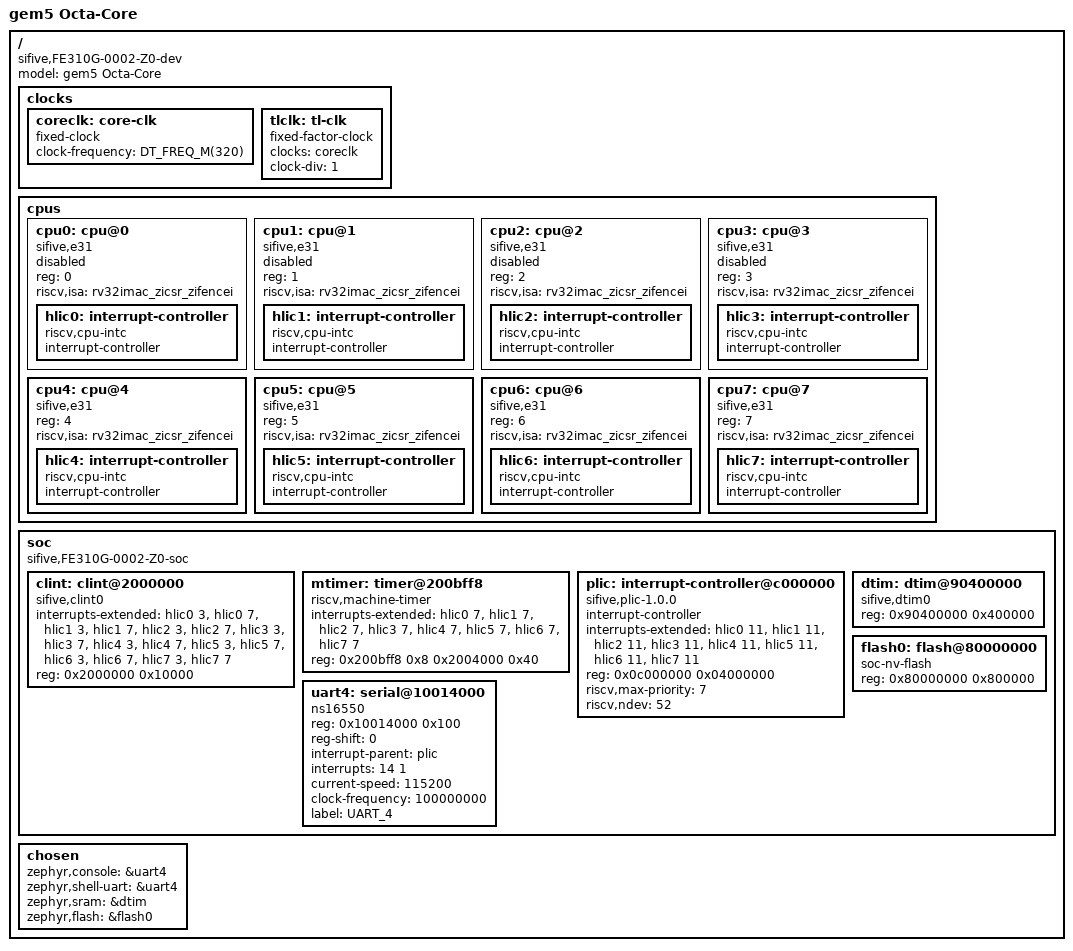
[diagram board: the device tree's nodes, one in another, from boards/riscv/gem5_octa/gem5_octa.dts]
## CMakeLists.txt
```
cmake_minimum_required(VERSION 3.20.0)
find_package(Zephyr REQUIRED HINTS $ENV{ZEPHYR_BASE})
project(smp_hello)

target_sources(app PRIVATE src/main.c)
```

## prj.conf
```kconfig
CONFIG_SMP=y
CONFIG_MP_MAX_NUM_CPUS=4
CONFIG_RV_BOOT_HART=4
CONFIG_RISCV_MACHINE_TIMER=y
CONFIG_SYS_CLOCK_TICKS_PER_SEC=100
CONFIG_XIP=n
```

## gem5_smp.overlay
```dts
/ {
	chosen {
		zephyr,console = &uart0;
		zephyr,shell-uart = &uart0;
		zephyr,sram = &dtim;
		zephyr,flash = &dtim;
	};
};

&uart0 {
    reg = <0x10014000 0x100>;
    interrupts = <14 1>;
    current-speed = <115200>;
    clock-frequency = <100000000>;
};

&dtim {
    reg = <0x90400000 0x400000>; /* 4MB Shared SRAM (Data) */
};

/delete-node/ &spi0;

/ {
    soc {
        flash0: memory@80000000 {
            compatible = "mmio-sram";
            reg = <0x80000000 0x800000>; /* 8MB Shared MRAM (Code) */
        };
    };
};
```

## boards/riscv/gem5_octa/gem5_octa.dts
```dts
/* SPDX-License-Identifier: Apache-2.0 */

/dts-v1/;

#include <zephyr/dt-bindings/gpio/gpio.h>
#include <zephyr/dt-bindings/pwm/pwm.h>
#include <freq.h>

/ {
	#address-cells = <1>;
	#size-cells = <1>;
	compatible = "sifive,FE310G-0002-Z0-dev", "fe310-dev", "sifive-dev";
	model = "gem5 Octa-Core";

	clocks {
		coreclk: core-clk {
			#clock-cells = <0>;
			compatible = "fixed-clock";
			clock-frequency = <DT_FREQ_M(320)>;
		};

		tlclk: tl-clk {
			#clock-cells = <0>;
			compatible = "fixed-factor-clock";
			clocks = <&coreclk>;
			clock-div = <1>;
		};
	};

	cpus {
		#address-cells = <1>;
		#size-cells = <0>;

		cpu0: cpu@0 {
			compatible = "sifive,e31", "riscv";
			device_type = "cpu";
			reg = <0>;
			riscv,isa = "rv32imac_zicsr_zifencei";
			status = "disabled";
			hlic0: interrupt-controller {
				compatible = "riscv,cpu-intc";
				#address-cells = <0>;
				#interrupt-cells = <1>;
				interrupt-controller;
			};
		};
        
        cpu1: cpu@1 {
			compatible = "sifive,e31", "riscv";
			device_type = "cpu";
			reg = <1>;
			riscv,isa = "rv32imac_zicsr_zifencei";
			status = "disabled";
			hlic1: interrupt-controller {
				compatible = "riscv,cpu-intc";
				#address-cells = <0>;
				#interrupt-cells = <1>;
				interrupt-controller;
			};
		};
        
        cpu2: cpu@2 {
			compatible = "sifive,e31", "riscv";
			device_type = "cpu";
			reg = <2>;
			riscv,isa = "rv32imac_zicsr_zifencei";
			status = "disabled";
			hlic2: interrupt-controller {
				compatible = "riscv,cpu-intc";
				#address-cells = <0>;
				#interrupt-cells = <1>;
				interrupt-controller;
			};
		};
        
        cpu3: cpu@3 {
			compatible = "sifive,e31", "riscv";
			device_type = "cpu";
			reg = <3>;
			riscv,isa = "rv32imac_zicsr_zifencei";
			status = "disabled";
			hlic3: interrupt-controller {
				compatible = "riscv,cpu-intc";
				#address-cells = <0>;
				#interrupt-cells = <1>;
				interrupt-controller;
			};
		};
        
        cpu4: cpu@4 {
			compatible = "sifive,e31", "riscv";
			device_type = "cpu";
			reg = <4>;
			riscv,isa = "rv32imac_zicsr_zifencei";
			status = "okay";
			hlic4: interrupt-controller {
				compatible = "riscv,cpu-intc";
				#address-cells = <0>;
				#interrupt-cells = <1>;
				interrupt-controller;
			};
		};
        
        cpu5: cpu@5 {
			compatible = "sifive,e31", "riscv";
			device_type = "cpu";
			reg = <5>;
			riscv,isa = "rv32imac_zicsr_zifencei";
			status = "okay";
			hlic5: interrupt-controller {
				compatible = "riscv,cpu-intc";
				#address-cells = <0>;
				#interrupt-cells = <1>;
				interrupt-controller;
			};
		};
        
        cpu6: cpu@6 {
			compatible = "sifive,e31", "riscv";
			device_type = "cpu";
			reg = <6>;
			riscv,isa = "rv32imac_zicsr_zifencei";
			status = "okay";
			hlic6: interrupt-controller {
				compatible = "riscv,cpu-intc";
				#address-cells = <0>;
				#interrupt-cells = <1>;
				interrupt-controller;
			};
		};
        
        cpu7: cpu@7 {
			compatible = "sifive,e31", "riscv";
			device_type = "cpu";
			reg = <7>;
			riscv,isa = "rv32imac_zicsr_zifencei";
			status = "okay";
			hlic7: interrupt-controller {
				compatible = "riscv,cpu-intc";
				#address-cells = <0>;
				#interrupt-cells = <1>;
				interrupt-controller;
			};
		};
	};

	soc {
		#address-cells = <1>;
		#size-cells = <1>;
		compatible = "sifive,FE310G-0002-Z0-soc", "fe310-soc",
			     "sifive-soc", "simple-bus";
		ranges;

		clint: clint@2000000 {
			compatible = "sifive,clint0";
			interrupts-extended = <&hlic0 3 &hlic0 7
                                   &hlic1 3 &hlic1 7
                                   &hlic2 3 &hlic2 7
                                   &hlic3 3 &hlic3 7
                                   &hlic4 3 &hlic4 7
                                   &hlic5 3 &hlic5 7
                                   &hlic6 3 &hlic6 7
                                   &hlic7 3 &hlic7 7>;
			reg = <0x2000000 0x10000>;
		};

		mtimer: timer@200bff8 {
			compatible = "riscv,machine-timer";
			interrupts-extended = <&hlic0 7 &hlic1 7 &hlic2 7 &hlic3 7 &hlic4 7 &hlic5 7 &hlic6 7 &hlic7 7>;
			reg = <0x200bff8 0x8 0x2004000 0x40>;
			reg-names = "mtime", "mtimecmp";
		};

		plic: interrupt-controller@c000000 {
			compatible = "sifive,plic-1.0.0";
			#address-cells = <0>;
			#interrupt-cells = <2>;
			interrupt-controller;
			interrupts-extended = <&hlic0 11
                                   &hlic1 11
                                   &hlic2 11
                                   &hlic3 11
                                   &hlic4 11
                                   &hlic5 11
                                   &hlic6 11
                                   &hlic7 11>;
			reg = <0x0c000000 0x04000000>;
			riscv,max-priority = <7>;
			riscv,ndev = <52>;
		};

		dtim: dtim@90400000 {
			compatible = "sifive,dtim0";
			reg = <0x90400000 0x400000>;
			reg-names = "mem";
		};
        
        flash0: flash@80000000 {
            compatible = "soc-nv-flash";
            reg = <0x80000000 0x800000>;
        };

		uart4: serial@10014000 {
			compatible = "ns16550";
			reg = <0x10014000 0x100>;
			reg-shift = <0>;
			interrupt-parent = <&plic>;
			interrupts = <14 1>;
			status = "okay";
			current-speed = <115200>;
			clock-frequency = <100000000>;
            label = "UART_4";
		};
	};
    
    chosen {
		zephyr,console = &uart4;
		zephyr,shell-uart = &uart4;
		zephyr,sram = &dtim;
		zephyr,flash = &flash0;
	};
};
```

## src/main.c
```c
/*
 * Copyright (c) 2012-2014 Wind River Systems, Inc.
 *
 * SPDX-License-Identifier: Apache-2.0
 */

#include <zephyr/kernel.h>
#include <zephyr/sys/printk.h>


#define STACK_SIZE 1024
#define PRIORITY 7

struct k_thread worker_threads[CONFIG_MP_MAX_NUM_CPUS];
K_THREAD_STACK_ARRAY_DEFINE(worker_stacks, CONFIG_MP_MAX_NUM_CPUS, STACK_SIZE);

void worker_entry(void *p1, void *p2, void *p3)
{
    int core_id = (int)(long)p1;
    ARG_UNUSED(p2);
    ARG_UNUSED(p3);

    while (1) {
        printk("Heartbeat from Core %d (Hart %d)\n", core_id, arch_proc_id());
        k_busy_wait(1000000); // 1 second roughly
        k_yield();
    }
}

int main(void)
{
	printk("Hello World from SMP Cluster 1! (Boot Core %d)\n", arch_proc_id());
    
    // Spawn threads for all cores (including this one)
    for (int i = 0; i < CONFIG_MP_MAX_NUM_CPUS; i++) {
        // We can't pin thread to core 0 easily if we are running on it?
        // Actually we can.
        // But main thread is already running on Core 0.
        // We'll spawn new threads.
        
        // Note: Zephyr doesn't strictly pin unless we use specific API or scheduler.
        // But usually creating a thread doesn't guarantee core.
        // However, we can use k_thread_create and let scheduler distribute.
        // Or we can just print from main loop for Core 0, and spawn for others?
        
        // Let's just spawn and hope scheduler distributes.
        // Or use k_thread_cpu_mask_clear/enable if available.
        
        k_thread_create(&worker_threads[i], worker_stacks[i],
                        STACK_SIZE, worker_entry,
                        (void *)(long)i, NULL, NULL,
                        PRIORITY, 0, K_NO_WAIT);
    }

    // Main thread can just sleep
    while (1) {
        k_sleep(K_FOREVER);
    }
	return 0;
}
```
